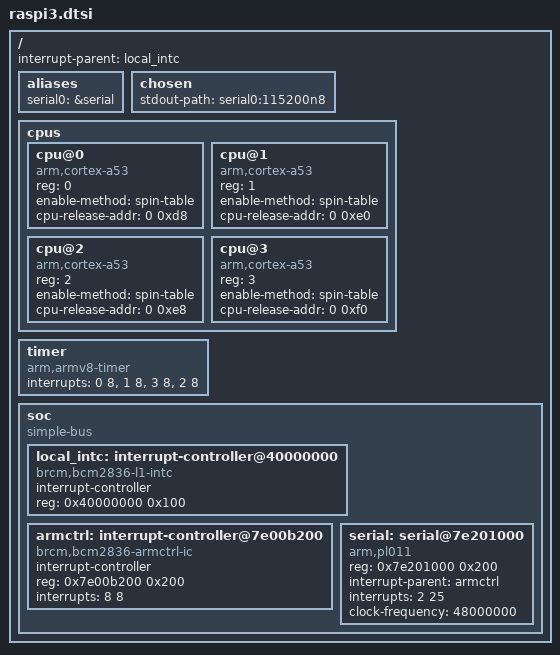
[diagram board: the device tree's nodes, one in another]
// Minimal QEMU BCM2837 description; physical boards need their firmware DTB.
// QEMU's AArch64 boot stub uses spin-table slots 0xd8..0xf0 in reserved low RAM.
/memreserve/ 0 0x100000;

/ {
    #address-cells = <2>;
    #size-cells = <1>;
    interrupt-parent = <&local_intc>;
    aliases { serial0 = &serial; };
    chosen { stdout-path = "serial0:115200n8"; };
    cpus {
        #address-cells = <1>;
        #size-cells = <0>;
        cpu@0 { device_type = "cpu"; compatible = "arm,cortex-a53"; reg = <0>;
                enable-method = "spin-table"; cpu-release-addr = <0 0xd8>; };
        cpu@1 { device_type = "cpu"; compatible = "arm,cortex-a53"; reg = <1>;
                enable-method = "spin-table"; cpu-release-addr = <0 0xe0>; };
        cpu@2 { device_type = "cpu"; compatible = "arm,cortex-a53"; reg = <2>;
                enable-method = "spin-table"; cpu-release-addr = <0 0xe8>; };
        cpu@3 { device_type = "cpu"; compatible = "arm,cortex-a53"; reg = <3>;
                enable-method = "spin-table"; cpu-release-addr = <0 0xf0>; };
    };
    timer {
        compatible = "arm,armv8-timer";
        interrupts = <0 8>, <1 8>, <3 8>, <2 8>;
    };
    soc {
        compatible = "simple-bus";
        #address-cells = <1>;
        #size-cells = <1>;
        ranges = <0x7e000000 0 0x3f000000 0x01000000>,
                 <0x40000000 0 0x40000000 0x100>;
        local_intc: interrupt-controller@40000000 {
            compatible = "brcm,bcm2836-l1-intc";
            #interrupt-cells = <2>;
            interrupt-controller;
            reg = <0x40000000 0x100>;
        };
        armctrl: interrupt-controller@7e00b200 {
            compatible = "brcm,bcm2836-armctrl-ic";
            #interrupt-cells = <2>;
            interrupt-controller;
            reg = <0x7e00b200 0x200>;
            interrupts = <8 8>;
        };
        serial: serial@7e201000 {
            compatible = "arm,pl011";
            reg = <0x7e201000 0x200>;
            interrupt-parent = <&armctrl>;
            interrupts = <2 25>;
            clock-frequency = <48000000>;
        };
    };
};
